# ESP32-S3 register map
Vendor: ESPRESSIF SYSTEMS (SHANGHAI) CO., LTD.; Series: ESP32 S-Series; File version: 22
CPU: Xtensa LX7 r0p0, little endian, no MPU, FPU, 0 interrupt priority bits
Address unit: 32 bits
Registers are 32-bit, read-write, reset 0x0 unless marked. A register's access mark holds for its fields unless they carry their own. Offsets are from the block's base; [hi:lo] are bit positions; {n}, {i} and the like mark numbered series.

## SPI0 — SPI (Serial Peripheral Interface) Controller 0
Base 0x60003000
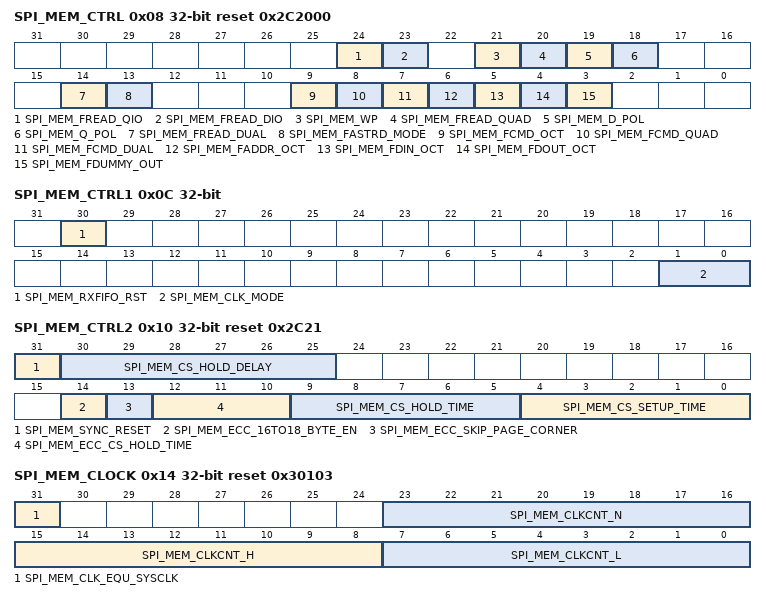
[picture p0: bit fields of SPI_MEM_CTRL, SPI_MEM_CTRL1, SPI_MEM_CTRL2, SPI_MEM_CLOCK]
0x08 SPI_MEM_CTRL reset 0x2C2000 — SPI0 control register.
  [24] SPI_MEM_FREAD_QIO — In hardware 0xEB read operation, ADDR phase and DIN phase apply 4 signals(4-bit-mode). 1: enable 0: disable.
  [23] SPI_MEM_FREAD_DIO — In hardware 0xBB read operation, ADDR phase and DIN phase apply 2 signals(2-bit-mode). 1: enable 0: disable.
  [21] SPI_MEM_WP — Write protect signal output when SPI is idle. 1: output high, 0: output low.
  [20] SPI_MEM_FREAD_QUAD — In hardware 0x6B read operation, DIN phase apply 4 signals(4-bit-mode). 1: enable 0: disable.
  [19] SPI_MEM_D_POL — The bit is used to set MOSI line polarity, 1: high 0, low
  [18] SPI_MEM_Q_POL — The bit is used to set MISO line polarity, 1: high 0, low
  [14] SPI_MEM_FREAD_DUAL — In hardware 0x3B read operation, DIN phase apply 2 signals. 1: enable 0: disable.
  [13] SPI_MEM_FASTRD_MODE — This bit should be set when SPI_MEM_FREAD_QIO, SPI_MEM_FREAD_DIO, SPI_MEM_FREAD_QUAD or SPI_MEM_FREAD_DUAL is set.
  [9] SPI_MEM_FCMD_OCT — Set this bit to enable 8-bit-mode(8-bm) in CMD phase.
  [8] SPI_MEM_FCMD_QUAD — Set this bit to enable 4-bit-mode(4-bm) in CMD phase.
  [7] SPI_MEM_FCMD_DUAL — Set this bit to enable 2-bit-mode(2-bm) in CMD phase.
  [6] SPI_MEM_FADDR_OCT — Set this bit to enable 8-bit-mode(8-bm) in ADDR phase.
  [5] SPI_MEM_FDIN_OCT — Set this bit to enable 8-bit-mode(8-bm) in DIN phase.
  [4] SPI_MEM_FDOUT_OCT — Set this bit to enable 8-bit-mode(8-bm) in DOUT phase.
  [3] SPI_MEM_FDUMMY_OUT — In the DUMMY phase the signal level of SPI bus is output by the SPI0 controller.
0x0C SPI_MEM_CTRL1 — SPI0 control 1 register.
  [30] SPI_MEM_RXFIFO_RST — SPI0 RX FIFO reset signal. Set this bit and clear it before SPI0 transfer starts.
  [1:0] SPI_MEM_CLK_MODE — SPI Bus clock (SPI_CLK) mode bits. 0: SPI Bus clock (SPI_CLK) is off when CS inactive 1: SPI_CLK is delayed one cycle after SPI_CS inactive 2: SPI_CLK is delayed two cycles after SPI_CS inactive 3: SPI_CLK is always on.
0x10 SPI_MEM_CTRL2 reset 0x2C21 — SPI0 control 2 register.
  [31] SPI_MEM_SYNC_RESET — The FSM will be reset.
  [30:25] SPI_MEM_CS_HOLD_DELAY — These bits are used to set the minimum CS high time tSHSL between SPI burst transfer when accesses to flash. tSHSL is (SPI_MEM_CS_HOLD_DELAY[5:0] + 1) MSPI core clock cycles.
  [14] SPI_MEM_ECC_16TO18_BYTE_EN — Set this bit to enable MSPI ECC 16 bytes data with 2 ECC bytes mode when accesses flash.
  [13] SPI_MEM_ECC_SKIP_PAGE_CORNER — 1: MSPI skips page corner when accesses flash. 0: Not skip page corner when accesses flash.
  [12:10] SPI_MEM_ECC_CS_HOLD_TIME — SPI_MEM_CS_HOLD_TIME + SPI_MEM_ECC_CS_HOLD_TIME is the SPI_CS hold cycle in ECC mode when accessed flash.
  [9:5] SPI_MEM_CS_HOLD_TIME — SPI Bus CS (SPI_CS) signal is delayed to inactive by SPI Bus clock (SPI_CLK), which is the SPI_CS hold time in non-ECC mode. These bits are combined with SPI_MEM_CS_HOLD bit.
  [4:0] SPI_MEM_CS_SETUP_TIME — (cycles-1) of PREP phase by SPI_CLK, which is the SPI_CS setup time. These bits are combined with SPI_MEM_CS_SETUP bit.
0x14 SPI_MEM_CLOCK reset 0x30103 — SPI_CLK clock division register when SPI0 accesses to flash.
  [31] SPI_MEM_CLK_EQU_SYSCLK — When SPI0 accesses flash, set this bit in 1-division mode, f_SPI_CLK = f_MSPI_CORE_CLK.
  [23:16] SPI_MEM_CLKCNT_N — When SPI0 accesses flash, f_SPI_CLK = f_MSPI_CORE_CLK/(SPI_MEM_CLKCNT_N+1)
  [15:8] SPI_MEM_CLKCNT_H — It must be a floor value of ((SPI_MEM_CLKCNT_N+1)/2-1).
  [7:0] SPI_MEM_CLKCNT_L — It must equal to the value of SPI_MEM_CLKCNT_N.
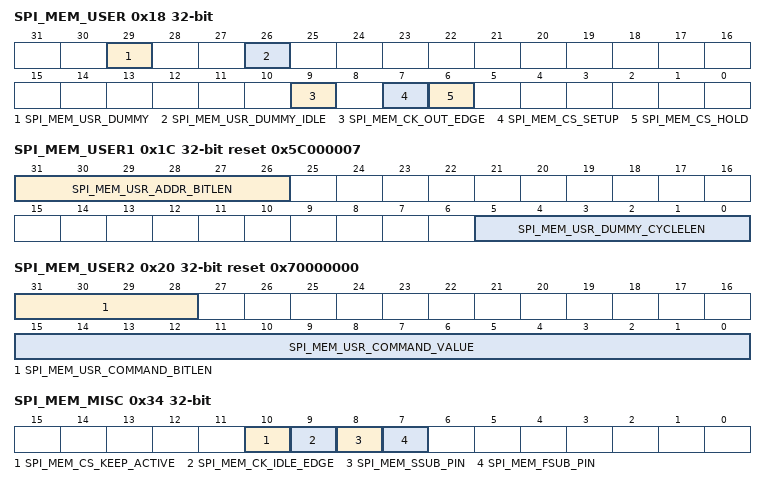
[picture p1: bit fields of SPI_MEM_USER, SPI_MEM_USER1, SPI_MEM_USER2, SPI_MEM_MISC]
0x18 SPI_MEM_USER — SPI0 user register.
  [29] SPI_MEM_USR_DUMMY — This bit enable the DUMMY phase of an SPI transfer.
  [26] SPI_MEM_USR_DUMMY_IDLE — SPI_CLK is disabled(No clock edges) in DUMMY phase when the bit is enable.
  [9] SPI_MEM_CK_OUT_EDGE — This bit, combined with SPI_MEM_CK_IDLE_EDGE bit, is used to change the clock mode 0~3 of SPI_CLK.
  [7] SPI_MEM_CS_SETUP — Set this bit to keep SPI_CS low when MSPI is in PREP state.
  [6] SPI_MEM_CS_HOLD — Set this bit to keep SPI_CS low when MSPI is in DONE state.
0x1C SPI_MEM_USER1 reset 0x5C000007 — SPI0 user1 register.
  [31:26] SPI_MEM_USR_ADDR_BITLEN — The length in bits of ADDR phase. The register value shall be (bit_num-1).
  [5:0] SPI_MEM_USR_DUMMY_CYCLELEN — The SPI_CLK cycle length minus 1 of DUMMY phase.
0x20 SPI_MEM_USER2 reset 0x70000000 — SPI0 user2 register.
  [31:28] SPI_MEM_USR_COMMAND_BITLEN — The length in bits of CMD phase. The register value shall be (bit_num-1)
  [15:0] SPI_MEM_USR_COMMAND_VALUE — The value of user defined(USR) command.
0x2C SPI_MEM_RD_STATUS — SPI0 read control register.
  [23:16] SPI_MEM_WB_MODE — Mode bits in the flash fast read mode it is combined with SPI_MEM_FASTRD_MODE bit.
0x30 SPI_MEM_EXT_ADDR — SPI0 extended address register.
  [31:0] SPI_MEM_EXT_ADDR — The register are the higher 32bits in the 64 bits address mode.
0x34 SPI_MEM_MISC — SPI0 misc register
  [10] SPI_MEM_CS_KEEP_ACTIVE — SPI_CS line keep low when the bit is set.
  [9] SPI_MEM_CK_IDLE_EDGE — 1: SPI_CLK line is high when idle. 0: SPI_CLK line is low when idle
  [8] SPI_MEM_SSUB_PIN — Ext_RAM is connected to SPI SUBPIN bus.
  [7] SPI_MEM_FSUB_PIN — Flash is connected to SPI SUBPIN bus.
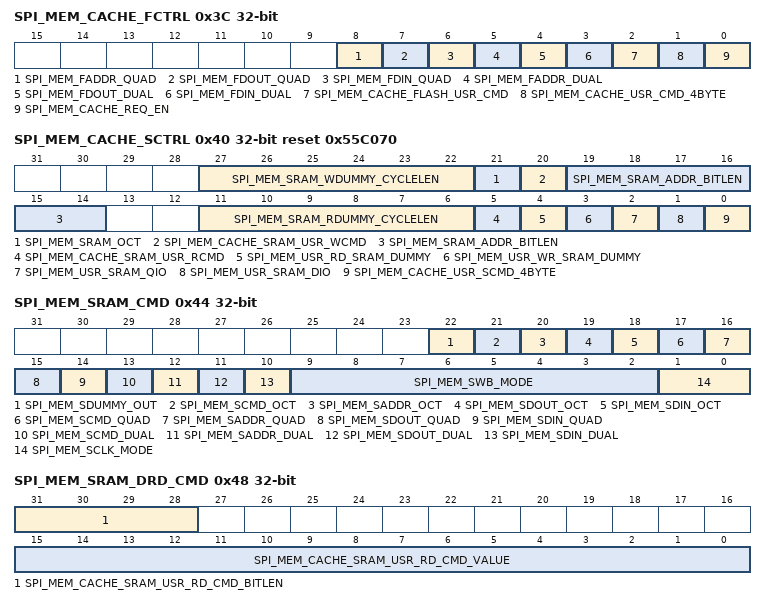
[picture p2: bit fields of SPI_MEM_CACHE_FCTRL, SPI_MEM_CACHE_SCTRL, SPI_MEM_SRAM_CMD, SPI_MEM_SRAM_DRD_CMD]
0x3C SPI_MEM_CACHE_FCTRL — SPI0 external RAM bit mode control register.
  [8] SPI_MEM_FADDR_QUAD — When SPI0 accesses to flash, set this bit to enable 4-bm in ADDR phase.
  [7] SPI_MEM_FDOUT_QUAD — When SPI0 accesses to flash, set this bit to enable 4-bm in DOUT phase.
  [6] SPI_MEM_FDIN_QUAD — When SPI0 accesses to flash, set this bit to enable 4-bm in DIN phase.
  [5] SPI_MEM_FADDR_DUAL — When SPI0 accesses to flash, set this bit to enable 2-bm in ADDR phase.
  [4] SPI_MEM_FDOUT_DUAL — When SPI0 accesses to flash, set this bit to enable 2-bm in DOUT phase.
  [3] SPI_MEM_FDIN_DUAL — When SPI0 accesses to flash, set this bit to enable 2-bm in DIN phase.
  [2] SPI_MEM_CACHE_FLASH_USR_CMD — 1: The command value of SPI0 reads flash is SPI_MEM_USR_COMMAND_VALUE. 0: Hardware read command value, controlled by SPI_MEM_FREAD_QIO, SPI_MEM_FREAD_DIO, SPI_MEM_FREAD_QUAD, SPI_MEM_FREAD_DUAL and SPI_MEM_FASTRD_MODE bits.
  [1] SPI_MEM_CACHE_USR_CMD_4BYTE — Set this bit to enable SPI0 read flash with 32 bits address. The value of SPI_MEM_USR_ADDR_BITLEN should be 31.
  [0] SPI_MEM_CACHE_REQ_EN — Set this bit to enable Cache's access and SPI0's transfer.
0x40 SPI_MEM_CACHE_SCTRL reset 0x55C070 — SPI0 external RAM control register
  [27:22] SPI_MEM_SRAM_WDUMMY_CYCLELEN — When SPI0 accesses to Ext_RAM, it is the SPI_CLK cycles minus 1 of DUMMY phase in write data transfer.
  [21] SPI_MEM_SRAM_OCT — Set the bit to enable OPI mode in all SPI0 Ext_RAM transfer.
  [20] SPI_MEM_CACHE_SRAM_USR_WCMD — 1: The command value of SPI0 write Ext_RAM is SPI_MEM_CACHE_SRAM_USR_RD_CMD_VALUE. 0: The value is 0x3.
  [19:14] SPI_MEM_SRAM_ADDR_BITLEN — When SPI0 accesses to Ext_RAM, it is the length in bits of ADDR phase. The register value shall be (bit_num-1).
  [11:6] SPI_MEM_SRAM_RDUMMY_CYCLELEN — When SPI0 accesses to Ext_RAM, it is the SPI_CLK cycles minus 1 of DUMMY phase in read data transfer.
  [5] SPI_MEM_CACHE_SRAM_USR_RCMD — 1: The command value of SPI0 read Ext_RAM is SPI_MEM_CACHE_SRAM_USR_WR_CMD_VALUE. 0: The value is 0x2.
  [4] SPI_MEM_USR_RD_SRAM_DUMMY — When SPI0 accesses to Ext_RAM, set this bit to enable DUMMY phase in read operations.
  [3] SPI_MEM_USR_WR_SRAM_DUMMY — When SPI0 accesses to Ext_RAM, set this bit to enable DUMMY phase in write operations.
  [2] SPI_MEM_USR_SRAM_QIO — Set the bit to enable QPI mode in all SPI0 Ext_RAM transfer.
  [1] SPI_MEM_USR_SRAM_DIO — Set the bit to enable 2-bm in all the phases of SPI0 Ext_RAM transfer.
  [0] SPI_MEM_CACHE_USR_SCMD_4BYTE — Set this bit to enable SPI0 read Ext_RAM with 32 bits address. The value of SPI_MEM_SRAM_ADDR_BITLEN should be 31.
0x44 SPI_MEM_SRAM_CMD — SPI0 external RAM mode control register
  [22] SPI_MEM_SDUMMY_OUT — When SPI0 accesses to Ext_RAM, in the DUMMY phase the signal level of SPI bus is output by the SPI0 controller.
  [21] SPI_MEM_SCMD_OCT — When SPI0 accesses to Ext_RAM, set this bit to enable 8-bm in CMD phase.
  [20] SPI_MEM_SADDR_OCT — When SPI0 accesses to Ext_RAM, set this bit to enable 8-bm in ADDR phase.
  [19] SPI_MEM_SDOUT_OCT — When SPI0 accesses to Ext_RAM, set this bit to enable 8-bm in DOUT phase.
  [18] SPI_MEM_SDIN_OCT — When SPI0 accesses to Ext_RAM, set this bit to enable 8-bm in DIN phase.
  [17] SPI_MEM_SCMD_QUAD — When SPI0 accesses to Ext_RAM, set this bit to enable 4-bm in CMD phase.
  [16] SPI_MEM_SADDR_QUAD — When SPI0 accesses to Ext_RAM, set this bit to enable 4-bm in ADDR phase.
  [15] SPI_MEM_SDOUT_QUAD — When SPI0 accesses to Ext_RAM, set this bit to enable 4-bm in DOUT phase.
  [14] SPI_MEM_SDIN_QUAD — When SPI0 accesses to Ext_RAM, set this bit to enable 4-bm in DIN phase.
  [13] SPI_MEM_SCMD_DUAL — When SPI0 accesses to Ext_RAM, set this bit to enable 2-bm in CMD phase.
  [12] SPI_MEM_SADDR_DUAL — When SPI0 accesses to Ext_RAM, set this bit to enable 2-bm in ADDR phase.
  [11] SPI_MEM_SDOUT_DUAL — When SPI0 accesses to Ext_RAM, set this bit to enable 2-bm in DOUT phase.
  [10] SPI_MEM_SDIN_DUAL — When SPI0 accesses to Ext_RAM, set this bit to enable 2-bm in DIN phase.
  [9:2] SPI_MEM_SWB_MODE — Mode bits when SPI0 accesses to Ext_RAM.
  [1:0] SPI_MEM_SCLK_MODE — SPI_CLK mode bits when SPI0 accesses to Ext_RAM. 0: SPI_CLK is off when CS inactive 1: SPI_CLK is delayed one cycle after CS inactive 2: SPI_CLK is delayed two cycles after CS inactive 3: SPI_CLK is always on.
0x48 SPI_MEM_SRAM_DRD_CMD — SPI0 external RAM DDR read command control register
  [31:28] SPI_MEM_CACHE_SRAM_USR_RD_CMD_BITLEN — When SPI0 reads Ext_RAM, it is the length in bits of CMD phase. The register value shall be (bit_num-1).
  [15:0] SPI_MEM_CACHE_SRAM_USR_RD_CMD_VALUE — When SPI0 reads Ext_RAM, it is the command value of CMD phase.
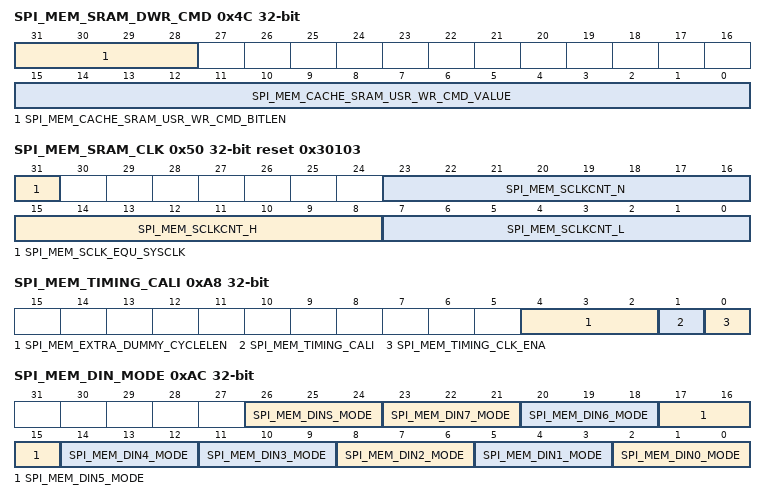
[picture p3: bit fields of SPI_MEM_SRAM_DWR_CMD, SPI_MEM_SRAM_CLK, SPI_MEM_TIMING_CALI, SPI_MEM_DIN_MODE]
0x4C SPI_MEM_SRAM_DWR_CMD — SPI0 external RAM DDR write command control register
  [31:28] SPI_MEM_CACHE_SRAM_USR_WR_CMD_BITLEN — When SPI0 writes Ext_RAM, it is the length in bits of CMD phase. The register value shall be (bit_num-1).
  [15:0] SPI_MEM_CACHE_SRAM_USR_WR_CMD_VALUE — When SPI0 writes Ext_RAM, it is the command value of CMD phase.
0x50 SPI_MEM_SRAM_CLK reset 0x30103 — SPI_CLK clock division register when SPI0 accesses to Ext_RAM.
  [31] SPI_MEM_SCLK_EQU_SYSCLK — When SPI0 accesses to Ext_RAM, set this bit in 1-division mode, f_SPI_CLK = f_MSPI_CORE_CLK.
  [23:16] SPI_MEM_SCLKCNT_N — When SPI0 accesses to Ext_RAM, f_SPI_CLK = f_MSPI_CORE_CLK/(SPI_MEM_SCLKCNT_N+1)
  [15:8] SPI_MEM_SCLKCNT_H — It must be a floor value of ((SPI_MEM_SCLKCNT_N+1)/2-1).
  [7:0] SPI_MEM_SCLKCNT_L — It must equal to the value of SPI_MEM_SCLKCNT_N.
0x54 SPI_MEM_FSM ro — SPI0 state machine(FSM) status register.
  [2:0] SPI_MEM_ST — The status of SPI0 state machine. 0: idle state(IDLE), 1: preparation state(PREP), 2: send command state(CMD), 3: send address state(ADDR), 4: red data state(DIN), 5:write data state(DOUT), 6: wait state(DUMMY), 7: done state(DONE).
0xA8 SPI_MEM_TIMING_CALI — SPI0 timing compensation register when accesses to flash.
  [4:2] SPI_MEM_EXTRA_DUMMY_CYCLELEN — Extra SPI_CLK cycles added in DUMMY phase for timing compensation, when SPI0 accesses to flash. Active when SPI_MEM_TIMING_CALI bit is set.
  [1] SPI_MEM_TIMING_CALI — Set this bit to add extra SPI_CLK cycles in DUMMY phase for all reading operations.
  [0] SPI_MEM_TIMING_CLK_ENA — Set this bit to power on HCLK. When PLL is powered on, the frequency of HCLK equals to that of PLL. Otherwise, the frequency equals to that of XTAL.
0xAC SPI_MEM_DIN_MODE — MSPI input timing delay mode control register when accesses to flash.
  [26:24] SPI_MEM_DINS_MODE — SPI_DQS input delay mode. 0: No delay. 1: Delay for (SPI_MEM_DINS_NUM+1) cycles at MSPI_CORE_CLK negative edge. 2: Delay for (SPI_MEM_DINS_NUM+1) cycles at HCLK positive edge and one cycle at MSPI_CORE_CLK positive edge. 3: Delay for (SPI_MEM_DINS_NUM+1) cycles at HCLK positive edge and one cycle at MSPI_CORE_CLK negative edge. 4: Delay for (SPI_MEM_DINS_NUM+1) cycles at HCLK negative edge and one cycle at MSPI_CORE_CLK positive edge. 5: Delay for (SPI_MEM_DINS_NUM+1) cycles at HCLK negative edge and one cycle at MSPI_CORE_CLK negative edge.
  [3n+2:3n] SPI_MEM_DIN{n}_MODE (n=4..7) — SPI_IO{n} input delay mode. 0: No delay. 1: Delay for (SPI_MEM_DIN{3n}_NUM+1) cycles at MSPI_CORE_CLK negative edge. 2: Delay for (SPI_MEM_DIN{3n}_NUM+1) cycles at HCLK positive edge and one cycle at MSPI_CORE_CLK positive edge. 3: Delay for (SPI_MEM_DIN{3n}_NUM+1) cycles at HCLK positive edge and one cycle at MSPI_CORE_CLK negative edge. 4: Delay for (SPI_MEM_DIN{3n}_NUM+1) cycles at HCLK negative edge and one cycle at MSPI_CORE_CLK positive edge. 5: Delay for (SPI_MEM_DIN{3n}_NUM+1) cycles at HCLK negative edge and one cycle at MSPI_CORE_CLK negative edge.
  [11:9] SPI_MEM_DIN3_MODE — SPI_HD input delay mode. 0: No delay. 1: Delay for (SPI_MEM_DIN9_NUM+1) cycles at MSPI_CORE_CLK negative edge. 2: Delay for (SPI_MEM_DIN9_NUM+1) cycles at HCLK positive edge and one cycle at MSPI_CORE_CLK positive edge. 3: Delay for (SPI_MEM_DIN9_NUM+1) cycles at HCLK positive edge and one cycle at MSPI_CORE_CLK negative edge. 4: Delay for (SPI_MEM_DIN9_NUM+1) cycles at HCLK negative edge and one cycle at MSPI_CORE_CLK positive edge. 5: Delay for (SPI_MEM_DIN9_NUM+1) cycles at HCLK negative edge and one cycle at MSPI_CORE_CLK negative edge.
  [8:6] SPI_MEM_DIN2_MODE — SPI_WP input delay mode. 0: No delay. 1: Delay for (SPI_MEM_DIN6_NUM+1) cycles at MSPI_CORE_CLK negative edge. 2: Delay for (SPI_MEM_DIN6_NUM+1) cycles at HCLK positive edge and one cycle at MSPI_CORE_CLK positive edge. 3: Delay for (SPI_MEM_DIN6_NUM+1) cycles at HCLK positive edge and one cycle at MSPI_CORE_CLK negative edge. 4: Delay for (SPI_MEM_DIN6_NUM+1) cycles at HCLK negative edge and one cycle at MSPI_CORE_CLK positive edge. 5: Delay for (SPI_MEM_DIN6_NUM+1) cycles at HCLK negative edge and one cycle at MSPI_CORE_CLK negative edge.
  [5:3] SPI_MEM_DIN1_MODE — SPI_Q input delay mode. 0: No delay. 1: Delay for (SPI_MEM_DIN3_NUM+1) cycles at MSPI_CORE_CLK negative edge. 2: Delay for (SPI_MEM_DIN3_NUM+1) cycles at HCLK positive edge and one cycle at MSPI_CORE_CLK positive edge. 3: Delay for (SPI_MEM_DIN3_NUM+1) cycles at HCLK positive edge and one cycle at MSPI_CORE_CLK negative edge. 4: Delay for (SPI_MEM_DIN3_NUM+1) cycles at HCLK negative edge and one cycle at MSPI_CORE_CLK positive edge. 5: Delay for (SPI_MEM_DIN3_NUM+1) cycles at HCLK negative edge and one cycle at MSPI_CORE_CLK negative edge.
  [2:0] SPI_MEM_DIN0_MODE — SPI_D input delay mode. 0: No delay. 1: Delay for (SPI_MEM_DIN0_NUM+1) cycles at MSPI_CORE_CLK negative edge. 2: Delay for (SPI_MEM_DIN0_NUM+1) cycles at HCLK positive edge and one cycle at MSPI_CORE_CLK positive edge. 3: Delay for (SPI_MEM_DIN0_NUM+1) cycles at HCLK positive edge and one cycle at MSPI_CORE_CLK negative edge. 4: Delay for (SPI_MEM_DIN0_NUM+1) cycles at HCLK negative edge and one cycle at MSPI_CORE_CLK positive edge. 5: Delay for (SPI_MEM_DIN0_NUM+1) cycles at HCLK negative edge and one cycle at MSPI_CORE_CLK negative edge.
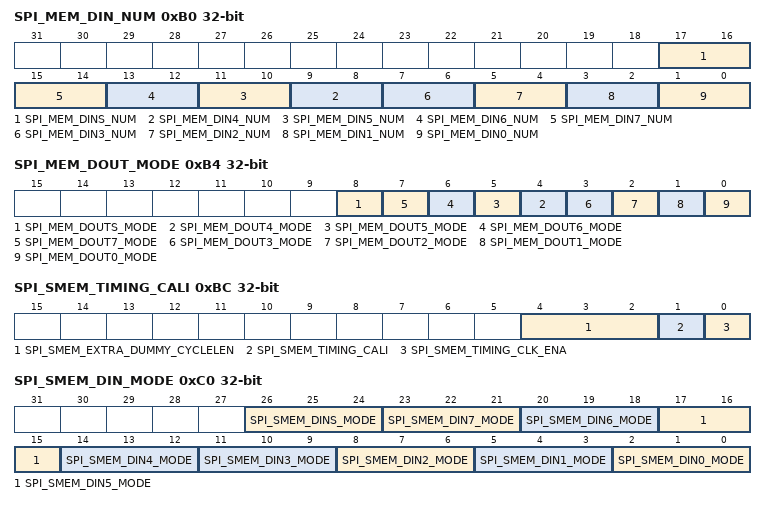
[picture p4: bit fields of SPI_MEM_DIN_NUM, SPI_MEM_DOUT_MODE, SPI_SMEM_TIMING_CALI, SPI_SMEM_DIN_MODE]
0xB0 SPI_MEM_DIN_NUM — MSPI input timing delay number control register when accesses to flash.
  [17:16] SPI_MEM_DINS_NUM — SPI_DQS input delay number.
  [2n+1:2n] SPI_MEM_DIN{n}_NUM (n=4..7) — SPI_IO{n} input delay number.
  [7:6] SPI_MEM_DIN3_NUM — SPI_HD input delay number.
  [5:4] SPI_MEM_DIN2_NUM — SPI_WP input delay number.
  [3:2] SPI_MEM_DIN1_NUM — SPI_Q input delay number.
  [1:0] SPI_MEM_DIN0_NUM — SPI_D input delay number.
0xB4 SPI_MEM_DOUT_MODE — MSPI output timing delay mode control register when accesses to flash.
  [8] SPI_MEM_DOUTS_MODE — SPI_DQS output delay mode. 0: No delay. 1: Delay one cycle at MSPI_CORE_CLK negative edge.
  [n] SPI_MEM_DOUT{n}_MODE (n=4..7) — SPI_IO{n} output delay mode. 0: No delay. 1: Delay one cycle at MSPI_CORE_CLK negative edge.
  [3] SPI_MEM_DOUT3_MODE — SPI_HD output delay mode. 0: No delay. 1: Delay one cycle at MSPI_CORE_CLK negative edge.
  [2] SPI_MEM_DOUT2_MODE — SPI_WP output delay mode. 0: No delay. 1: Delay one cycle at MSPI_CORE_CLK negative edge.
  [1] SPI_MEM_DOUT1_MODE — SPI_Q output delay mode. 0: No delay. 1: Delay one cycle at MSPI_CORE_CLK negative edge.
  [0] SPI_MEM_DOUT0_MODE — SPI_D output delay mode. 0: No delay. 1: Delay one cycle at MSPI_CORE_CLK negative edge.
0xBC SPI_SMEM_TIMING_CALI — SPI0 Ext_RAM timing compensation register.
  [4:2] SPI_SMEM_EXTRA_DUMMY_CYCLELEN — Extra SPI_CLK cycles added in DUMMY phase for timing compensation, when SPI0 accesses to Ext_RAM. Active when SPI_SMEM_TIMING_CALI bit is set.
  [1] SPI_SMEM_TIMING_CALI — Set this bit to add extra SPI_CLK cycles in DUMMY phase for all reading operations.
  [0] SPI_SMEM_TIMING_CLK_ENA — Set this bit to power on HCLK. When PLL is powered on, the frequency of HCLK equals to that of PLL. Otherwise, the frequency equals to that of XTAL.
0xC0 SPI_SMEM_DIN_MODE — MSPI input timing delay mode control register when accesses to Ext_RAM.
  [26:24] SPI_SMEM_DINS_MODE — SPI_DQS input delay mode. 0: No delay. 1: Delay for (SPI_SMEM_DINS_NUM+1) cycles at MSPI_CORE_CLK negative edge. 2: Delay for (SPI_SMEM_DINS_NUM+1) cycles at HCLK positive edge and one cycle at MSPI_CORE_CLK positive edge. 3: Delay for (SPI_SMEM_DINS_NUM+1) cycles at HCLK positive edge and one cycle at MSPI_CORE_CLK negative edge. 4: Delay for (SPI_SMEM_DINS_NUM+1) cycles at HCLK negative edge and one cycle at MSPI_CORE_CLK positive edge. 5: Delay for (SPI_SMEM_DINS_NUM+1) cycles at HCLK negative edge and one cycle at MSPI_CORE_CLK negative edge.
  [3n+2:3n] SPI_SMEM_DIN{n}_MODE (n=4..7) — SPI_IO{n} input delay mode. 0: No delay. 1: Delay for (SPI_SMEM_DIN{3n}_NUM+1) cycles at MSPI_CORE_CLK negative edge. 2: Delay for (SPI_SMEM_DIN{3n}_NUM+1) cycles at HCLK positive edge and one cycle at MSPI_CORE_CLK positive edge. 3: Delay for (SPI_SMEM_DIN{3n}_NUM+1) cycles at HCLK positive edge and one cycle at MSPI_CORE_CLK negative edge. 4: Delay for (SPI_SMEM_DIN{3n}_NUM+1) cycles at HCLK negative edge and one cycle at MSPI_CORE_CLK positive edge. 5: Delay for (SPI_SMEM_DIN{3n}_NUM+1) cycles at HCLK negative edge and one cycle at MSPI_CORE_CLK negative edge.
  [11:9] SPI_SMEM_DIN3_MODE — SPI_HD input delay mode. 0: No delay. 1: Delay for (SPI_SMEM_DIN9_NUM+1) cycles at MSPI_CORE_CLK negative edge. 2: Delay for (SPI_SMEM_DIN9_NUM+1) cycles at HCLK positive edge and one cycle at MSPI_CORE_CLK positive edge. 3: Delay for (SPI_SMEM_DIN9_NUM+1) cycles at HCLK positive edge and one cycle at MSPI_CORE_CLK negative edge. 4: Delay for (SPI_SMEM_DIN9_NUM+1) cycles at HCLK negative edge and one cycle at MSPI_CORE_CLK positive edge. 5: Delay for (SPI_SMEM_DIN9_NUM+1) cycles at HCLK negative edge and one cycle at MSPI_CORE_CLK negative edge.
  [8:6] SPI_SMEM_DIN2_MODE — SPI_WP input delay mode. 0: No delay. 1: Delay for (SPI_SMEM_DIN6_NUM+1) cycles at MSPI_CORE_CLK negative edge. 2: Delay for (SPI_SMEM_DIN6_NUM+1) cycles at HCLK positive edge and one cycle at MSPI_CORE_CLK positive edge. 3: Delay for (SPI_SMEM_DIN6_NUM+1) cycles at HCLK positive edge and one cycle at MSPI_CORE_CLK negative edge. 4: Delay for (SPI_SMEM_DIN6_NUM+1) cycles at HCLK negative edge and one cycle at MSPI_CORE_CLK positive edge. 5: Delay for (SPI_SMEM_DIN6_NUM+1) cycles at HCLK negative edge and one cycle at MSPI_CORE_CLK negative edge.
  [5:3] SPI_SMEM_DIN1_MODE — SPI_Q input delay mode. 0: No delay. 1: Delay for (SPI_SMEM_DIN3_NUM+1) cycles at MSPI_CORE_CLK negative edge. 2: Delay for (SPI_SMEM_DIN3_NUM+1) cycles at HCLK positive edge and one cycle at MSPI_CORE_CLK positive edge. 3: Delay for (SPI_SMEM_DIN3_NUM+1) cycles at HCLK positive edge and one cycle at MSPI_CORE_CLK negative edge. 4: Delay for (SPI_SMEM_DIN3_NUM+1) cycles at HCLK negative edge and one cycle at MSPI_CORE_CLK positive edge. 5: Delay for (SPI_SMEM_DIN3_NUM+1) cycles at HCLK negative edge and one cycle at MSPI_CORE_CLK negative edge.
  [2:0] SPI_SMEM_DIN0_MODE — SPI_D input delay mode. 0: No delay. 1: Delay for (SPI_SMEM_DIN0_NUM+1) cycles at MSPI_CORE_CLK negative edge. 2: Delay for (SPI_SMEM_DIN0_NUM+1) cycles at HCLK positive edge and one cycle at MSPI_CORE_CLK positive edge. 3: Delay for (SPI_SMEM_DIN0_NUM+1) cycles at HCLK positive edge and one cycle at MSPI_CORE_CLK negative edge. 4: Delay for (SPI_SMEM_DIN0_NUM+1) cycles at HCLK negative edge and one cycle at MSPI_CORE_CLK positive edge. 5: Delay for (SPI_SMEM_DIN0_NUM+1) cycles at HCLK negative edge and one cycle at MSPI_CORE_CLK negative edge.
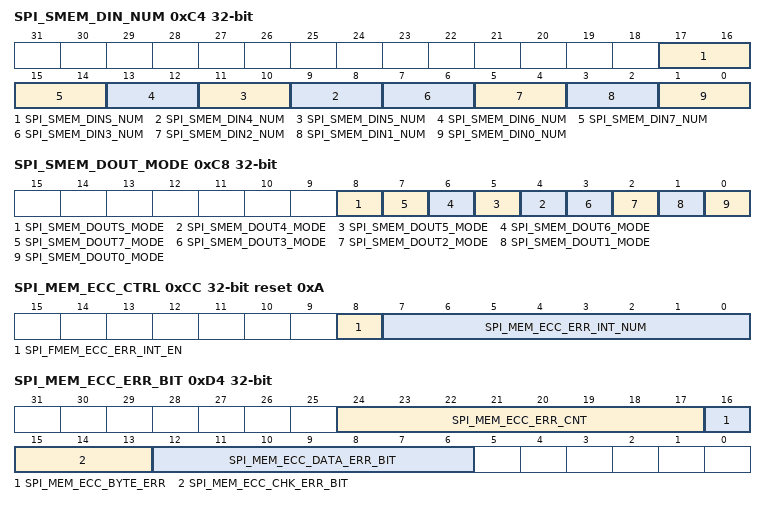
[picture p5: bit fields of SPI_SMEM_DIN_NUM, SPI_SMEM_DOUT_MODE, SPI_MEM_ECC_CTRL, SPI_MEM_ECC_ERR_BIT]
0xC4 SPI_SMEM_DIN_NUM — MSPI input timing delay number control register when accesses to Ext_RAM.
  [17:16] SPI_SMEM_DINS_NUM — SPI_DQS input delay number.
  [2n+1:2n] SPI_SMEM_DIN{n}_NUM (n=4..7) — SPI_IO{n} input delay number.
  [7:6] SPI_SMEM_DIN3_NUM — SPI_HD input delay number.
  [5:4] SPI_SMEM_DIN2_NUM — SPI_WP input delay number.
  [3:2] SPI_SMEM_DIN1_NUM — SPI_Q input delay number.
  [1:0] SPI_SMEM_DIN0_NUM — SPI_D input delay number.
0xC8 SPI_SMEM_DOUT_MODE — MSPI output timing delay mode control register when accesses to Ext_RAM.
  [8] SPI_SMEM_DOUTS_MODE — SPI_DQS output delay mode. 0: No delay. 1: Delay one cycle at MSPI_CORE_CLK negative edge.
  [n] SPI_SMEM_DOUT{n}_MODE (n=4..7) — SPI_IO{n} output delay mode. 0: No delay. 1: Delay one cycle at MSPI_CORE_CLK negative edge.
  [3] SPI_SMEM_DOUT3_MODE — SPI_HD output delay mode. 0: No delay. 1: Delay one cycle at MSPI_CORE_CLK negative edge.
  [2] SPI_SMEM_DOUT2_MODE — SPI_WP output delay mode. 0: No delay. 1: Delay one cycle at MSPI_CORE_CLK negative edge.
  [1] SPI_SMEM_DOUT1_MODE — SPI_Q output delay mode. 0: No delay. 1: Delay one cycle at MSPI_CORE_CLK negative edge.
  [0] SPI_SMEM_DOUT0_MODE — SPI_D output delay mode. 0: No delay. 1: Delay one cycle at MSPI_CORE_CLK negative edge.
0xCC SPI_MEM_ECC_CTRL reset 0xA — MSPI ECC control register
  [8] SPI_FMEM_ECC_ERR_INT_EN — Set this bit to calculate the error times of MSPI ECC read when accesses to flash.
  [7:0] SPI_MEM_ECC_ERR_INT_NUM — Set the error times of MSPI ECC read to generate MSPI SPI_MEM_ECC_ERR_INT interrupt.
0xD0 SPI_MEM_ECC_ERR_ADDR ro — MSPI ECC error address register
  [31:0] SPI_MEM_ECC_ERR_ADDR — These bits show the first MSPI ECC error address when SPI_FMEM_ECC_ERR_INT_EN/SPI_SMEM_ECC_ERR_INT_EN is set and accessed to flash/Ext_RAM, including ECC byte error and data error. It is cleared by when SPI_MEM_ECC_ERR_INT_CLR bit is set.
0xD4 SPI_MEM_ECC_ERR_BIT ro — MSPI ECC error bits register
  [24:17] SPI_MEM_ECC_ERR_CNT — This bits show the error times of MSPI ECC read, including ECC byte error and data byte error. It is cleared by when SPI_MEM_ECC_ERR_INT_CLR bit is set.
  [16] SPI_MEM_ECC_BYTE_ERR — It records the first ECC byte error when SPI_FMEM_ECC_ERR_INT_EN/SPI_SMEM_ECC_ERR_INT_EN is set and accessed to flash/Ext_RAM. It is cleared by SPI_MEM_ECC_ERR_INT_CLR bit.
  [15:13] SPI_MEM_ECC_CHK_ERR_BIT — When SPI_MEM_ECC_BYTE_ERR is set, these bits show the error bit number of ECC byte.
  [12:6] SPI_MEM_ECC_DATA_ERR_BIT — It records the first ECC data error bit number when SPI_FMEM_ECC_ERR_INT_EN/SPI_SMEM_ECC_ERR_INT_EN is set and accessed to flash/Ext_RAM. The value ranges from 0~127, corresponding to the bit number in 16 data bytes. It is cleared by SPI_MEM_ECC_ERR_INT_CLR bit.
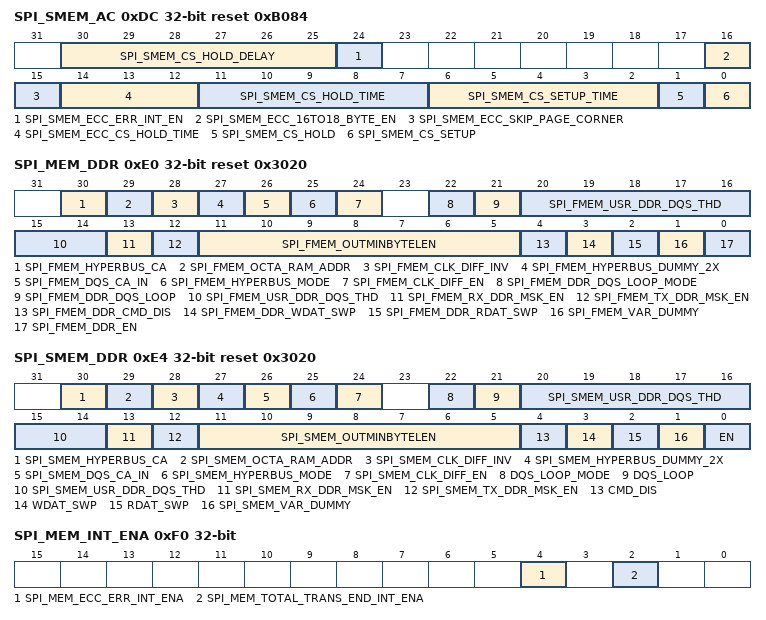
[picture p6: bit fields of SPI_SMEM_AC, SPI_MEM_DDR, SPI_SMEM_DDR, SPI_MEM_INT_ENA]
0xDC SPI_SMEM_AC reset 0xB084 — MSPI external RAM ECC and SPI CS timing control register
  [30:25] SPI_SMEM_CS_HOLD_DELAY — These bits are used to set the minimum CS high time tSHSL between SPI burst transfer when accesses to external RAM. tSHSL is (SPI_SMEM_CS_HOLD_DELAY[5:0] + 1) MSPI core clock cycles.
  [24] SPI_SMEM_ECC_ERR_INT_EN — Set this bit to calculate the error times of MSPI ECC read when accesses to external RAM.
  [16] SPI_SMEM_ECC_16TO18_BYTE_EN — Set this bit to enable MSPI ECC 16 bytes data with 2 ECC bytes mode when accesses to external RAM.
  [15] SPI_SMEM_ECC_SKIP_PAGE_CORNER — 1: MSPI skips page corner when accesses to external RAM. 0: Not skip page corner when accesses to external RAM.
  [14:12] SPI_SMEM_ECC_CS_HOLD_TIME — SPI_SMEM_CS_HOLD_TIME + SPI_SMEM_ECC_CS_HOLD_TIME is the MSPI CS hold cycles in ECC mode when accesses to external RAM.
  [11:7] SPI_SMEM_CS_HOLD_TIME — SPI Bus CS (SPI_CS) signal is delayed to inactive by SPI Bus clock (SPI_CLK), which is the SPI_CS hold time in non-ECC mode. These bits are combined with SPI_MEM_CS_HOLD bit.
  [6:2] SPI_SMEM_CS_SETUP_TIME — (cycles-1) of PREP phase by SPI_CLK, which is the SPI_CS setup time. These bits are combined with SPI_MEM_CS_SETUP bit.
  [1] SPI_SMEM_CS_HOLD — Set this bit to keep SPI_CS low when MSPI is in DONE state.
  [0] SPI_SMEM_CS_SETUP — Set this bit to keep SPI_CS low when MSPI is in PREP state.
0xE0 SPI_MEM_DDR reset 0x3020 — SPI0 flash DDR mode control register
  [30] SPI_FMEM_HYPERBUS_CA — Set this bit to enable HyperRAM address out when accesses to flash, which means ADDR_OUT[31:0] = {spi_usr_addr_value[19:4], 13'd0, spi_usr_addr_value[3:1]}.
  [29] SPI_FMEM_OCTA_RAM_ADDR — Set this bit to enable octa_ram address out when accesses to flash, which means ADDR_OUT[31:0] = {spi_usr_addr_value[25:4], 6'd0, spi_usr_addr_value[3:1], 1'b0}.
  [28] SPI_FMEM_CLK_DIFF_INV — Set this bit to invert SPI_DIFF when accesses to flash. .
  [27] SPI_FMEM_HYPERBUS_DUMMY_2X — Set this bit to enable the vary dummy function in SPI HyperBus mode, when SPI0 accesses to flash or SPI1 accesses flash or sram.
  [26] SPI_FMEM_DQS_CA_IN — Set this bit to enable the input of SPI_DQS signal in SPI phases of CMD and ADDR.
  [25] SPI_FMEM_HYPERBUS_MODE — Set this bit to enable the SPI HyperBus mode.
  [24] SPI_FMEM_CLK_DIFF_EN — Set this bit to enable the differential SPI_CLK#.
  [22] SPI_FMEM_DDR_DQS_LOOP_MODE — When SPI_FMEM_DDR_DQS_LOOP and SPI_FMEM_DDR_EN are set, 1: Use internal SPI_CLK as data strobe. 0: Use internal ~SPI_CLK as data strobe. Otherwise this bit is not active.
  [21] SPI_FMEM_DDR_DQS_LOOP — 1: Use internal signal as data strobe, the strobe can not be delayed by input timing module. 0: Use input SPI_DQS signal from PAD as data strobe, the strobe can be delayed by input timing module
  [20:14] SPI_FMEM_USR_DDR_DQS_THD — The delay number of data strobe which from memory based on SPI_CLK.
  [13] SPI_FMEM_RX_DDR_MSK_EN — Set this bit to mask the first or the last byte in MSPI ECC DDR read mode, when accesses to flash.
  [12] SPI_FMEM_TX_DDR_MSK_EN — Set this bit to mask the first or the last byte in MSPI ECC DDR write mode, when accesses to flash.
  [11:5] SPI_FMEM_OUTMINBYTELEN — It is the minimum output data length in the panda device.
  [4] SPI_FMEM_DDR_CMD_DIS — the bit is used to disable dual edge in CMD phase when ddr mode.
  [3] SPI_FMEM_DDR_WDAT_SWP — Set the bit to swap TX data of a word in DDR mode.
  [2] SPI_FMEM_DDR_RDAT_SWP — Set the bit to reorder RX data of the word in DDR mode.
  [1] SPI_FMEM_VAR_DUMMY — Set the bit to enable variable dummy cycle in DDR mode.
  [0] SPI_FMEM_DDR_EN — 1: in ddr mode, 0 in sdr mode
0xE4 SPI_SMEM_DDR reset 0x3020 — SPI0 external RAM DDR mode control register
  [30] SPI_SMEM_HYPERBUS_CA — Set this bit to enable HyperRAM address out when accesses to external RAM, which means ADDR_OUT[31:0] = {spi_usr_addr_value[19:4], 13'd0, spi_usr_addr_value[3:1]}.
  [29] SPI_SMEM_OCTA_RAM_ADDR — Set this bit to enable octa_ram address out when accesses to external RAM, which means ADDR_OUT[31:0] = {spi_usr_addr_value[25:4], 6'd0, spi_usr_addr_value[3:1], 1'b0}.
  [28] SPI_SMEM_CLK_DIFF_INV — Set this bit to invert SPI_DIFF when accesses to external RAM. .
  [27] SPI_SMEM_HYPERBUS_DUMMY_2X — Set this bit to enable the vary dummy function in SPI HyperBus mode, when SPI0 accesses to flash or SPI1 accesses flash or sram.
  [26] SPI_SMEM_DQS_CA_IN — Set this bit to enable the input of SPI_DQS signal in SPI phases of CMD and ADDR.
  [25] SPI_SMEM_HYPERBUS_MODE — Set this bit to enable the SPI HyperBus mode.
  [24] SPI_SMEM_CLK_DIFF_EN — Set this bit to enable the differential SPI_CLK#.
  [22] DQS_LOOP_MODE — When SPI_SMEM_DDR_DQS_LOOP and SPI_SMEM_DDR_EN are set, 1: Use internal SPI_CLK as data strobe. 0: Use internal ~SPI_CLK as data strobe. Otherwise this bit is not active.
  [21] DQS_LOOP — 1: Use internal signal as data strobe, the strobe can not be delayed by input timing module. 0: Use input SPI_DQS signal from PAD as data strobe, the strobe can be delayed by input timing module
  [20:14] SPI_SMEM_USR_DDR_DQS_THD — The delay number of data strobe which from memory based on SPI_CLK.
  [13] SPI_SMEM_RX_DDR_MSK_EN — Set this bit to mask the first or the last byte in MSPI ECC DDR read mode, when accesses to external RAM.
  [12] SPI_SMEM_TX_DDR_MSK_EN — Set this bit to mask the first or the last byte in MSPI ECC DDR write mode, when accesses to external RAM.
  [11:5] SPI_SMEM_OUTMINBYTELEN — It is the minimum output data length in the ddr psram.
  [4] CMD_DIS — the bit is used to disable dual edge in CMD phase when ddr mode.
  [3] WDAT_SWP — Set the bit to reorder tx data of the word in spi ddr mode.
  [2] RDAT_SWP — Set the bit to reorder rx data of the word in spi ddr mode.
  [1] SPI_SMEM_VAR_DUMMY — Set the bit to enable variable dummy cycle in spi ddr mode.
  [0] EN — 1: in ddr mode, 0 in sdr mode
0xE8 SPI_MEM_CLOCK_GATE reset 0x1 — SPI0 clk_gate register
  [0] SPI_MEM_CLK_EN — Register clock gate enable signal. 1: Enable. 0: Disable.
0xEC SPI_MEM_CORE_CLK_SEL — SPI0 module clock select register
  [1:0] SPI_MEM_CORE_CLK_SEL — When the digital system clock selects PLL clock and the frequency of PLL clock is 480MHz, the value of SPI_MEM_CORE_CLK_SEL: 0: SPI0/1 module clock (MSPI_CORE_CLK) is 80MHz. 1: MSPI_CORE_CLK is 120MHz. 2: MSPI_CORE_CLK is 160MHz. 3: MSPI_CORE_CLK is 240MHz. When the digital system clock selects PLL clock and the frequency of PLL clock is 320MHz, the value of SPI_MEM_CORE_CLK_SEL: 0: MSPI_CORE_CLK is 80MHz. 1: MSPI_CORE_CLK is 80MHz. 2: MSPI_CORE_CLK 160MHz. 3: Not used.
0xF0 SPI_MEM_INT_ENA — SPI1 interrupt enable register
  [4] SPI_MEM_ECC_ERR_INT_ENA — The enable bit for SPI_MEM_ECC_ERR_INT interrupt.
  [2] SPI_MEM_TOTAL_TRANS_END_INT_ENA — The enable bit for SPI_MEM_TOTAL_TRANS_END_INT interrupt.
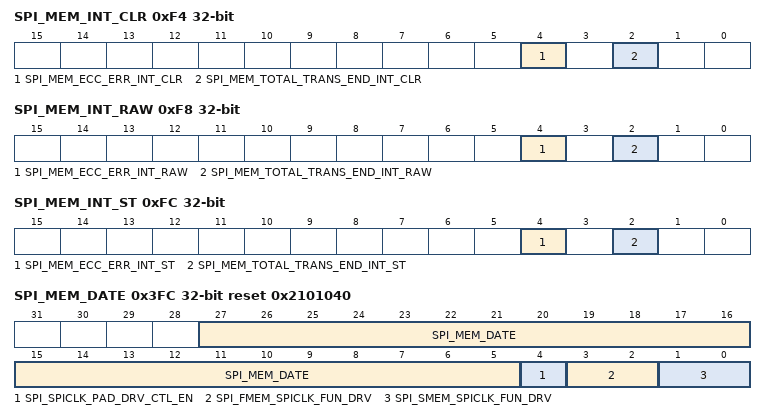
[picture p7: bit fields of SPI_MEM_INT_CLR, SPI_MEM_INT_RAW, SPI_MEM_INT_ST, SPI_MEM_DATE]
0xF4 SPI_MEM_INT_CLR wo — SPI1 interrupt clear register
  [4] SPI_MEM_ECC_ERR_INT_CLR — The clear bit for SPI_MEM_ECC_ERR_INT interrupt. SPI_MEM_ECC_ERR_ADDR and SPI_MEM_ECC_ERR_CNT will be cleared by the pulse of this bit.
  [2] SPI_MEM_TOTAL_TRANS_END_INT_CLR — The clear bit for SPI_MEM_TOTAL_TRANS_END_INT interrupt.
0xF8 SPI_MEM_INT_RAW — SPI1 interrupt raw register
  [4] SPI_MEM_ECC_ERR_INT_RAW — The raw bit for SPI_MEM_ECC_ERR_INT interrupt. When APB_CTRL_FECC_ERR_INT_EN is set and APB_CTRL_SECC_ERR_INT_EN is cleared, this bit is triggered when the error times of SPI0/1 ECC read flash are equal or bigger than APB_CTRL_ECC_ERR_INT_NUM. When APB_CTRL_FECC_ERR_INT_EN is cleared and APB_CTRL_SECC_ERR_INT_EN is set, this bit is triggered when the error times of SPI0/1 ECC read external RAM are equal or bigger than APB_CTRL_ECC_ERR_INT_NUM. When APB_CTRL_FECC_ERR_INT_EN and APB_CTRL_SECC_ERR_INT_EN are set, this bit is triggered when the total error times of SPI0/1 ECC read external RAM and flash are equal or bigger than APB_CTRL_ECC_ERR_INT_NUM. When APB_CTRL_FECC_ERR_INT_EN and APB_CTRL_SECC_ERR_INT_EN are cleared, this bit will not be triggered.
  [2] SPI_MEM_TOTAL_TRANS_END_INT_RAW — The raw bit for SPI_MEM_TOTAL_TRANS_END_INT interrupt. 1: Triggered when SPI1 transfer is done and flash is already idle. When WRSR/PP/SE/BE/CE is sent and PES/PER command is sent, this bit is set when WRSR/PP/SE/BE/CE is success. 0: Others.
0xFC SPI_MEM_INT_ST ro — SPI1 interrupt status register
  [4] SPI_MEM_ECC_ERR_INT_ST — The status bit for SPI_MEM_ECC_ERR_INT interrupt.
  [2] SPI_MEM_TOTAL_TRANS_END_INT_ST — The status bit for SPI_MEM_TOTAL_TRANS_END_INT interrupt.
0x3FC SPI_MEM_DATE reset 0x2101040 — SPI0 version control register
  [27:5] SPI_MEM_DATE — SPI register version.
  [4] SPI_SPICLK_PAD_DRV_CTL_EN — SPI_CLK PAD driver control signal. 1: The driver of SPI_CLK PAD is controlled by the bits SPI_FMEM_SPICLK_FUN_DRV[1:0] and SPI_SMEM_SPICLK_FUN_DRV[1:0]. 0: The driver of SPI_CLK PAD is controlled by the bits IO_MUX_FUNC_DRV[1:0] of SPICLK PAD.
  [3:2] SPI_FMEM_SPICLK_FUN_DRV — The driver of SPI_CLK PAD is controlled by the bits SPI_FMEM_SPICLK_FUN_DRV[1:0] when the bit SPI_SPICLK_PAD_DRV_CTL_EN is set and MSPI accesses to flash.
  [1:0] SPI_SMEM_SPICLK_FUN_DRV — The driver of SPI_CLK PAD is controlled by the bits SPI_SMEM_SPICLK_FUN_DRV[1:0] when the bit SPI_SPICLK_PAD_DRV_CTL_EN is set and MSPI accesses to external RAM.
